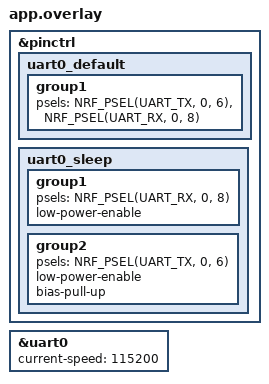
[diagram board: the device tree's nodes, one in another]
&pinctrl {
	uart0_default: uart0_default {
		group1 {
			psels = <NRF_PSEL(UART_TX, 0, 6)>,
				<NRF_PSEL(UART_RX, 0, 8)>;
		};
	};

	uart0_sleep: uart0_sleep {
		group1 {
			psels = <NRF_PSEL(UART_RX, 0, 8)>;
			low-power-enable;
		};

		group2 {
			psels = <NRF_PSEL(UART_TX, 0, 6)>;
			low-power-enable;
			bias-pull-up;
		};
	};
};

&uart0 {
	status = "okay";
	current-speed = <115200>;
	/delete-property/ hw-flow-control;
};

